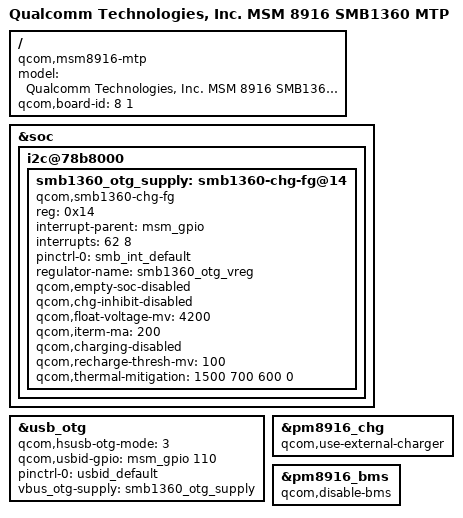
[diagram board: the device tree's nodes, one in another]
/* Copyright (c) 2014, The Linux Foundation. All rights reserved.
*
* This program is free software; you can redistribute it and/or modify
* it under the terms of the GNU General Public License version 2 and
* only version 2 as published by the Free Software Foundation.
*
* This program is distributed in the hope that it will be useful,
* but WITHOUT ANY WARRANTY; without even the implied warranty of
* MERCHANTABILITY or FITNESS FOR A PARTICULAR PURPOSE.  See the
* GNU General Public License for more details.
*/

/dts-v1/;

#include "msm8916-mtp.dtsi"
#include "msm8916-memory.dtsi"

/ {
	model = "Qualcomm Technologies, Inc. MSM 8916 SMB1360 MTP";
	compatible = "qcom,msm8916-mtp", "qcom,msm8916", "qcom,mtp";
	qcom,board-id = <8 1>;
};

&soc {
	i2c@78b8000 {
		smb1360_otg_supply: smb1360-chg-fg@14 {
			compatible = "qcom,smb1360-chg-fg";
			reg = <0x14>;
			interrupt-parent = <&msm_gpio>;
			interrupts = <62 8>;
			pinctrl-names = "default";
			pinctrl-0 = <&smb_int_default>;
			regulator-name = "smb1360_otg_vreg";

			qcom,empty-soc-disabled;
			qcom,chg-inhibit-disabled;
			qcom,float-voltage-mv = <4200>;
			qcom,iterm-ma = <200>;
			qcom,charging-disabled;
			qcom,recharge-thresh-mv = <100>;
			qcom,thermal-mitigation = <1500 700 600 0>;
		};
	};
};

&usb_otg {
	qcom,hsusb-otg-mode = <3>;
	qcom,usbid-gpio = <&msm_gpio 110 0>;
	pinctrl-names = "default";
	pinctrl-0 = <&usbid_default>;
	vbus_otg-supply = <&smb1360_otg_supply>;
};

&pm8916_chg {
	status = "ok";
	qcom,use-external-charger;
};

&pm8916_bms {
	status = "ok";
	qcom,disable-bms;
};
